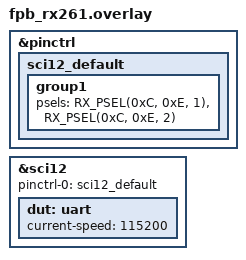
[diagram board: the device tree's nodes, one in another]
/*
 * Copyright (c) 2025 Renesas Electronics Corporation
 *
 * SPDX-License-Identifier: Apache-2.0
 */

&pinctrl {
	sci12_default: sci12_default {
		group1 {
			psels = <RX_PSEL(0xC, 0xE, 1)>,	/* PE1 (TXD12) */
			<RX_PSEL(0xC, 0xE, 2)>;  /* PE2 (RXD12) */
		};
	};
};

&sci12 {
	pinctrl-0 = <&sci12_default>;
	pinctrl-names = "default";
	status = "okay";

	dut: uart {
		current-speed = <115200>;
		status = "okay";
	};
};
